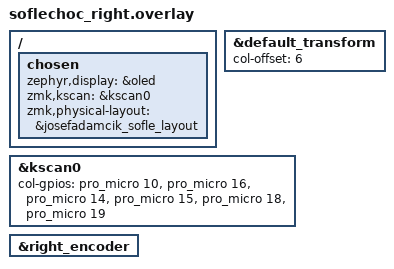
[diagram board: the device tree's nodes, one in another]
#include "soflechoc.dtsi"

/ {
    chosen {
        zephyr,display = &oled;
        zmk,kscan = &kscan0;
        zmk,physical-layout = &josefadamcik_sofle_layout;
    };
};

&default_transform {
    col-offset = <6>;
};

&kscan0 {
    col-gpios
        = <&pro_micro 10 GPIO_ACTIVE_HIGH>
        , <&pro_micro 16 GPIO_ACTIVE_HIGH>
        , <&pro_micro 14 GPIO_ACTIVE_HIGH>
        , <&pro_micro 15 GPIO_ACTIVE_HIGH>
        , <&pro_micro 18 GPIO_ACTIVE_HIGH>
        , <&pro_micro 19 GPIO_ACTIVE_HIGH>
        ;
};

&right_encoder {
    status = "okay";
};
